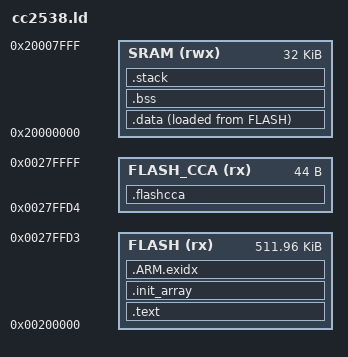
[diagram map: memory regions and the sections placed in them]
/*
 *  Copyright (c) 2016, The OpenThread Authors.
 *  All rights reserved.
 *
 *  Redistribution and use in source and binary forms, with or without
 *  modification, are permitted provided that the following conditions are met:
 *  1. Redistributions of source code must retain the above copyright
 *     notice, this list of conditions and the following disclaimer.
 *  2. Redistributions in binary form must reproduce the above copyright
 *     notice, this list of conditions and the following disclaimer in the
 *     documentation and/or other materials provided with the distribution.
 *  3. Neither the name of the copyright holder nor the
 *     names of its contributors may be used to endorse or promote products
 *     derived from this software without specific prior written permission.
 *
 *  THIS SOFTWARE IS PROVIDED BY THE COPYRIGHT HOLDERS AND CONTRIBUTORS "AS IS"
 *  AND ANY EXPRESS OR IMPLIED WARRANTIES, INCLUDING, BUT NOT LIMITED TO, THE
 *  IMPLIED WARRANTIES OF MERCHANTABILITY AND FITNESS FOR A PARTICULAR PURPOSE
 *  ARE DISCLAIMED. IN NO EVENT SHALL THE COPYRIGHT HOLDER OR CONTRIBUTORS BE
 *  LIABLE FOR ANY DIRECT, INDIRECT, INCIDENTAL, SPECIAL, EXEMPLARY, OR
 *  CONSEQUENTIAL DAMAGES (INCLUDING, BUT NOT LIMITED TO, PROCUREMENT OF
 *  SUBSTITUTE GOODS OR SERVICES; LOSS OF USE, DATA, OR PROFITS; OR BUSINESS
 *  INTERRUPTION) HOWEVER CAUSED AND ON ANY THEORY OF LIABILITY, WHETHER IN
 *  CONTRACT, STRICT LIABILITY, OR TORT (INCLUDING NEGLIGENCE OR OTHERWISE)
 *  ARISING IN ANY WAY OUT OF THE USE OF THIS SOFTWARE, EVEN IF ADVISED OF THE
 *  POSSIBILITY OF SUCH DAMAGE.
 */

/**
 * @file
 *   GCC linker script for CC2538.
 */

MEMORY
{
  FLASH (rx) :           ORIGIN = 0x00200000,            LENGTH = 0x0007FFD4
  FLASH_CCA (rx) :       ORIGIN = 0x0027FFD4,            LENGTH = 0x2C
  SRAM (rwx) :           ORIGIN = 0x20000000,            LENGTH = 32K
}

ENTRY(flash_cca_lock_page)
SECTIONS
{
    .text : ALIGN(4)
    {
        _text = .;
        *(.vectors)
        *(.text*)
        *(.rodata*)
        KEEP(*(.init))
        KEEP(*(.fini))
        _etext = .;
    } > FLASH= 0

    .init_array :
    {
        _init_array = .;
        KEEP(*(SORT(.init_array.*)))
        KEEP(*(.init_array*))
        _einit_array = .;
    } > FLASH

    .ARM.exidx : ALIGN(4)
    {
        *(.ARM.exidx*)
    } > FLASH

    .data : ALIGN(4)
    {
        _data = .;
        *(.data*)
        _edata = .;
    } > SRAM AT > FLASH
    _ldata = LOADADDR(.data);

    .bss : ALIGN(4)
    {
        _bss = .;
        *(.bss*)
        *(COMMON)
        _ebss = .;
    } > SRAM

    _heap = .;
    end = .;

    .stack : ALIGN(4)
    {
        *(.stack)
    } > SRAM

    .flashcca :
    {
        KEEP(*(.flash_cca))
    } > FLASH_CCA
}
